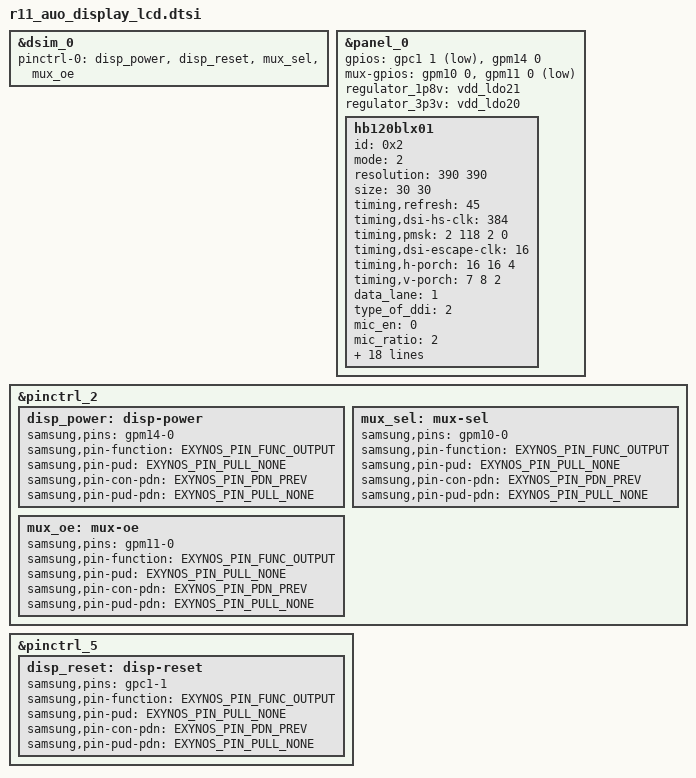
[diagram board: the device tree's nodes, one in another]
#include <dt-bindings/gpio/gpio.h>

&dsim_0 {
	pinctrl-names = "default";
	pinctrl-0 = <&disp_power &disp_reset &mux_sel &mux_oe>;
};

&panel_0 {
	/* reset, power */
	gpios = <&gpc1 1 GPIO_ACTIVE_LOW>, <&gpm14 0 GPIO_ACTIVE_HIGH>;
	mux-gpios = <&gpm10 0 GPIO_ACTIVE_HIGH>, <&gpm11 0 GPIO_ACTIVE_LOW>;
	regulator_1p8v = "vdd_ldo21";
	regulator_3p3v = "vdd_ldo20";

	hb120blx01: hb120blx01 {
		id = <0x2>;
		/* 0: video mode, 1: DP command mode, 2: MIPI command mode */
		mode = <2>;
		resolution = <390 390>;
		size = <30 30>;
		timing,refresh = <45>;
		/* TODO: Set below 3 timing parameters to be correct values */
		timing,dsi-hs-clk = <384>;
		timing,pmsk = <2 118 2 0>;
		timing,dsi-escape-clk = <16>;

		timing,h-porch = <16 16 4>; /* dsim H porch : hbp, hfp, hsa */
		timing,v-porch = <7 8 2>; /* dsim V porch : VBP, VFP, VSA */

		data_lane = <1>;
		type_of_ddi = <2>;

		/* Rest of parameters copied from exynos9110-display-lcd.dtsi */
		mic_en = <0>; /* 0: Disable, 1: Enable */
		mic_ratio = <2>; /* 0: 1/2 mic, 1: 1/3 mic */
		mic_ver = <2>; /* 0: mic v1.1, 1: v1.2, 2: v2.0 */
		dsc_en = <0>; /* 0: Disable, 1: Enable */
		dsc_cnt = <2>; /* used DSC count */
		dsc_slice_num = <2>; /* count of dsc slice */
		dsc_slice_h = <40>; /* height of dsc slice */
		cmd_underrun_lp_ref = <1625>; /* for underrun detect*/
		mres_en = <0>;
		mres_number = <1>;
		mres_width = <720>;
		mres_height = <1280>;
		mres_dsc_width = <360>;
		mres_dsc_height = <74>;
		mres_dsc_en = <0>;
		hdr_num = <0>;			/* not support */
		hdr_type = <0 0 0 0>;	/* not support */
		hdr_max_luma = <0>;		/* not support */
		hdr_max_avg_luma = <0>;	/* not support */
		hdr_min_luma = <0>;		/* not support */

	};

};

&pinctrl_2 {
	disp_power: disp-power {
		samsung,pins = "gpm14-0";
		samsung,pin-function = <EXYNOS_PIN_FUNC_OUTPUT>;
		samsung,pin-pud = <EXYNOS_PIN_PULL_NONE>;
		samsung,pin-con-pdn = <EXYNOS_PIN_PDN_PREV>;
		samsung,pin-pud-pdn = <EXYNOS_PIN_PULL_NONE>;
	};
	mux_sel: mux-sel {
		samsung,pins = "gpm10-0";
		samsung,pin-function = <EXYNOS_PIN_FUNC_OUTPUT>;
		samsung,pin-pud = <EXYNOS_PIN_PULL_NONE>;
		samsung,pin-con-pdn = <EXYNOS_PIN_PDN_PREV>;
		samsung,pin-pud-pdn = <EXYNOS_PIN_PULL_NONE>;
	};
	mux_oe: mux-oe {
		samsung,pins = "gpm11-0";
		samsung,pin-function = <EXYNOS_PIN_FUNC_OUTPUT>;
		samsung,pin-pud = <EXYNOS_PIN_PULL_NONE>;
		samsung,pin-con-pdn = <EXYNOS_PIN_PDN_PREV>;
		samsung,pin-pud-pdn = <EXYNOS_PIN_PULL_NONE>;
	};
};

&pinctrl_5 {
	disp_reset: disp-reset {
		samsung,pins = "gpc1-1";
		samsung,pin-function = <EXYNOS_PIN_FUNC_OUTPUT>;
		samsung,pin-pud = <EXYNOS_PIN_PULL_NONE>;
		samsung,pin-con-pdn = <EXYNOS_PIN_PDN_PREV>;
		samsung,pin-pud-pdn = <EXYNOS_PIN_PULL_NONE>;
	};
};
